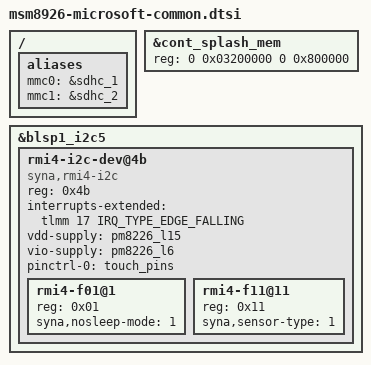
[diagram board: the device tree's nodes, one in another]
/* Copyright (c) 2013, The Linux Foundation. All rights reserved.
 * Copyright (c) 2025, Vicente Iñaki Cortés Cortés.
 *
 * This program is free software; you can redistribute it and/or modify
 * it under the terms of the GNU General Public License version 2 and
 * only version 2 as published by the Free Software Foundation.
 *
 * This program is distributed in the hope that it will be useful,
 * but WITHOUT ANY WARRANTY; without even the implied warranty of
 * MERCHANTABILITY or FITNESS FOR A PARTICULAR PURPOSE.  See the
 * GNU General Public License for more details.
 */

#include "qcom-pm8226.dtsi"
#include "msm8926-v2.dtsi"

/ {
	aliases {
		mmc0 = &sdhc_1; /* eMMC */
		mmc1 = &sdhc_2; /* MicroSD */
	};
};

&cont_splash_mem {
	reg = <0 0x03200000 0 0x800000>;
};

&blsp1_i2c5 {
	status = "okay";

	rmi4-i2c-dev@4b {
		compatible = "syna,rmi4-i2c";
		reg = <0x4b>;
		#address-cells = <1>;
		#size-cells = <0>;

		interrupts-extended = <&tlmm 17 IRQ_TYPE_EDGE_FALLING>;
		vdd-supply = <&pm8226_l15>;
		vio-supply = <&pm8226_l6>;

		pinctrl-names = "default";
		pinctrl-0 = <&touch_pins>;

		rmi4-f01@1 {
			reg = <0x01>;
			syna,nosleep-mode = <1>;
		};

		rmi4-f11@11 {
			reg = <0x11>;
			syna,sensor-type = <1>;
		};
	};
};
